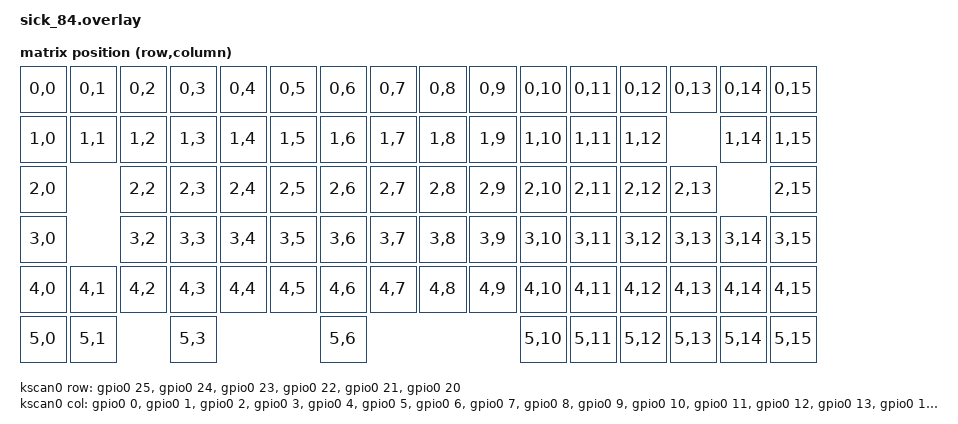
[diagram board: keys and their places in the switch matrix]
// This file was generated from a template. Edit it to match your keyboard.
// See https://zmk.dev/docs/development/new-shield for more instructions.

#include <dt-bindings/zmk/matrix_transform.h>
#include <physical_layouts.dtsi>

/ {
    chosen {
        zmk,kscan = &kscan0;
        // zmk,matrix_transform = &default_transform;
        zmk,physical-layout = &default_layout;
    };

    default_transform: default_transform {
        compatible = "zmk,matrix-transform";
        columns = <16>;
        rows = <6>;
        map = <
            RC(0, 0) RC(0, 1) RC(0, 2) RC(0, 3) RC(0, 4) RC(0, 5) RC(0, 6) RC(0, 7) RC(0, 8) RC(0, 9) RC(0, 10) RC(0, 11) RC(0, 12) RC(0, 13) RC(0, 14) RC(0, 15)
            RC(1, 0) RC(1, 1) RC(1, 2) RC(1, 3) RC(1, 4) RC(1, 5) RC(1, 6) RC(1, 7) RC(1, 8) RC(1, 9) RC(1, 10) RC(1, 11) RC(1, 12)           RC(1, 14) RC(1, 15)
            RC(2, 0)          RC(2, 2) RC(2, 3) RC(2, 4) RC(2, 5) RC(2, 6) RC(2, 7) RC(2, 8) RC(2, 9) RC(2, 10) RC(2, 11) RC(2, 12) RC(2, 13)           RC(2, 15)
            RC(3, 0)          RC(3, 2) RC(3, 3) RC(3, 4) RC(3, 5) RC(3, 6) RC(3, 7) RC(3, 8) RC(3, 9) RC(3, 10) RC(3, 11) RC(3, 12) RC(3, 13) RC(3, 14) RC(3, 15)
            RC(4, 0) RC(4, 1) RC(4, 2) RC(4, 3) RC(4, 4) RC(4, 5) RC(4, 6) RC(4, 7) RC(4, 8) RC(4, 9) RC(4, 10) RC(4, 11) RC(4, 12) RC(4, 13) RC(4, 14) RC(4, 15)
            RC(5, 0) RC(5, 1)          RC(5, 3)                   RC(5, 6)                            RC(5, 10) RC(5, 11) RC(5, 12) RC(5, 13) RC(5, 14) RC(5, 15)
        >;
    };

    kscan0: kscan {
        compatible = "zmk,kscan-gpio-matrix";
        diode-direction = "col2row";
        wakeup-source;

        col-gpios
            = <&gpio0 0 GPIO_ACTIVE_HIGH>
            , <&gpio0 1 GPIO_ACTIVE_HIGH>
            , <&gpio0 2 GPIO_ACTIVE_HIGH>
            , <&gpio0 3 GPIO_ACTIVE_HIGH>
            , <&gpio0 4 GPIO_ACTIVE_HIGH>
            , <&gpio0 5 GPIO_ACTIVE_HIGH>
            , <&gpio0 6 GPIO_ACTIVE_HIGH>
            , <&gpio0 7 GPIO_ACTIVE_HIGH>
            , <&gpio0 8 GPIO_ACTIVE_HIGH>
            , <&gpio0 9 GPIO_ACTIVE_HIGH>
            , <&gpio0 10 GPIO_ACTIVE_HIGH>
            , <&gpio0 11 GPIO_ACTIVE_HIGH>
            , <&gpio0 12 GPIO_ACTIVE_HIGH>
            , <&gpio0 13 GPIO_ACTIVE_HIGH>
            , <&gpio0 14 GPIO_ACTIVE_HIGH>
            , <&gpio0 15 GPIO_ACTIVE_HIGH>
            ;

        row-gpios
            = <&gpio0 25 (GPIO_ACTIVE_HIGH | GPIO_PULL_DOWN)>
            , <&gpio0 24 (GPIO_ACTIVE_HIGH | GPIO_PULL_DOWN)>
            , <&gpio0 23 (GPIO_ACTIVE_HIGH | GPIO_PULL_DOWN)>
            , <&gpio0 22 (GPIO_ACTIVE_HIGH | GPIO_PULL_DOWN)>
            , <&gpio0 21 (GPIO_ACTIVE_HIGH | GPIO_PULL_DOWN)>
            , <&gpio0 20 (GPIO_ACTIVE_HIGH | GPIO_PULL_DOWN)>
            ;
    };

    default_layout: default_layout {
        compatible = "zmk,physical-layout";
        display-name = "Default Layout";
        transform = <&default_transform>;
        kscan = <&kscan0>;
        keys
            // 0 row :               w   h    x    y     rot    rx    ry
            = <&key_physical_attrs 100 100    0    0       0     0     0> 
            , <&key_physical_attrs 100 100  100    0       0     0     0>
            , <&key_physical_attrs 100 100  200    0       0     0     0>
            , <&key_physical_attrs 100 100  300    0       0     0     0>
            , <&key_physical_attrs 100 100  400    0       0     0     0>
            , <&key_physical_attrs 100 100  500    0       0     0     0>
            , <&key_physical_attrs 100 100  600    0       0     0     0>
            , <&key_physical_attrs 100 100  700    0       0     0     0>
            , <&key_physical_attrs 100 100  800    0       0     0     0>
            , <&key_physical_attrs 100 100  900    0       0     0     0>
            , <&key_physical_attrs 100 100  1000   0       0     0     0>
            , <&key_physical_attrs 100 100  1100   0       0     0     0>
            , <&key_physical_attrs 100 100  1200   0       0     0     0>
            , <&key_physical_attrs 100 100  1300   0       0     0     0>
            , <&key_physical_attrs 100 100  1400   0       0     0     0>
            , <&key_physical_attrs 100 100  1500   0       0     0     0>
            // 1 row :               w   h    x    y     rot    rx    ry
            , <&key_physical_attrs 100 100    0   100       0     0     0> 
            , <&key_physical_attrs 100 100  100   100       0     0     0>
            , <&key_physical_attrs 100 100  200   100       0     0     0>
            , <&key_physical_attrs 100 100  300   100       0     0     0>
            , <&key_physical_attrs 100 100  400   100       0     0     0>
            , <&key_physical_attrs 100 100  500   100       0     0     0>
            , <&key_physical_attrs 100 100  600   100       0     0     0>
            , <&key_physical_attrs 100 100  700   100       0     0     0>
            , <&key_physical_attrs 100 100  800   100       0     0     0>
            , <&key_physical_attrs 100 100  900   100       0     0     0>
            , <&key_physical_attrs 100 100  1000  100       0     0     0>
            , <&key_physical_attrs 100 100  1100  100       0     0     0>
            , <&key_physical_attrs 100 100  1200  100       0     0     0>
            , <&key_physical_attrs 200 100  1300  100       0     0     0>
            , <&key_physical_attrs 100 100  1500  100       0     0     0>
            // 2 row :               w   h    x    y     rot    rx    ry
            , <&key_physical_attrs 150 100    0   200       0     0     0> 
            , <&key_physical_attrs 100 100  150   200       0     0     0>
            , <&key_physical_attrs 100 100  250   200       0     0     0>
            , <&key_physical_attrs 100 100  350   200       0     0     0>
            , <&key_physical_attrs 100 100  450   200       0     0     0>
            , <&key_physical_attrs 100 100  550   200       0     0     0>
            , <&key_physical_attrs 100 100  650   200       0     0     0>
            , <&key_physical_attrs 100 100  750   200       0     0     0>
            , <&key_physical_attrs 100 100  850   200       0     0     0>
            , <&key_physical_attrs 100 100  950   200       0     0     0>
            , <&key_physical_attrs 100 100  1050  200       0     0     0>
            , <&key_physical_attrs 100 100  1150  200       0     0     0>
            , <&key_physical_attrs 100 100  1250  200       0     0     0>
            , <&key_physical_attrs 125 200  1375  200       0     0     0>
            , <&key_physical_attrs 100 100  1500  200       0     0     0>
            // 3 row :               w   h    x    y     rot    rx    ry
            , <&key_physical_attrs 175 100    0   300       0     0     0> 
            , <&key_physical_attrs 100 100  175   300       0     0     0>
            , <&key_physical_attrs 100 100  275   300       0     0     0>
            , <&key_physical_attrs 100 100  375   300       0     0     0>
            , <&key_physical_attrs 100 100  475   300       0     0     0>
            , <&key_physical_attrs 100 100  575   300       0     0     0>
            , <&key_physical_attrs 100 100  675   300       0     0     0>
            , <&key_physical_attrs 100 100  775   300       0     0     0>
            , <&key_physical_attrs 100 100  875   300       0     0     0>
            , <&key_physical_attrs 100 100  975   300       0     0     0>
            , <&key_physical_attrs 100 100  1075  300       0     0     0>
            , <&key_physical_attrs 100 100  1175  300       0     0     0>
            , <&key_physical_attrs 100 100  1275  300       0     0     0>
            , <&key_physical_attrs 100 100  1500  300       0     0     0>
            // 4 row :               w   h    x    y     rot    rx    ry
            , <&key_physical_attrs 125 100    0   400       0     0     0> 
            , <&key_physical_attrs 100 100  125   400       0     0     0>
            , <&key_physical_attrs 100 100  225   400       0     0     0>
            , <&key_physical_attrs 100 100  325   400       0     0     0>
            , <&key_physical_attrs 100 100  425   400       0     0     0>
            , <&key_physical_attrs 100 100  525   400       0     0     0>
            , <&key_physical_attrs 100 100  625   400       0     0     0>
            , <&key_physical_attrs 100 100  725   400       0     0     0>
            , <&key_physical_attrs 100 100  825   400       0     0     0>
            , <&key_physical_attrs 100 100  925   400       0     0     0>
            , <&key_physical_attrs 100 100  1025  400       0     0     0>
            , <&key_physical_attrs 100 100  1125  400       0     0     0>
            , <&key_physical_attrs 175 100  1225  400       0     0     0>
            , <&key_physical_attrs 100 100  1400  400       0     0     0>
            , <&key_physical_attrs 100 100  1500  400       0     0     0>
            // 5 row :               w   h    x    y     rot    rx    ry
            , <&key_physical_attrs 125 100    0   500       0     0     0> 
            , <&key_physical_attrs 125 100  125   500       0     0     0>
            , <&key_physical_attrs 125 100  250   500       0     0     0>
            , <&key_physical_attrs 625 100  375   500       0     0     0>
            , <&key_physical_attrs 100 100  1000  500       0     0     0>
            , <&key_physical_attrs 100 100  1100  500       0     0     0>
            , <&key_physical_attrs 100 100  1200  500       0     0     0>
            , <&key_physical_attrs 100 100  1300  500       0     0     0>
            , <&key_physical_attrs 100 100  1400  500       0     0     0>
            , <&key_physical_attrs 100 100  1500  500       0     0     0>
            ;
    };
};
